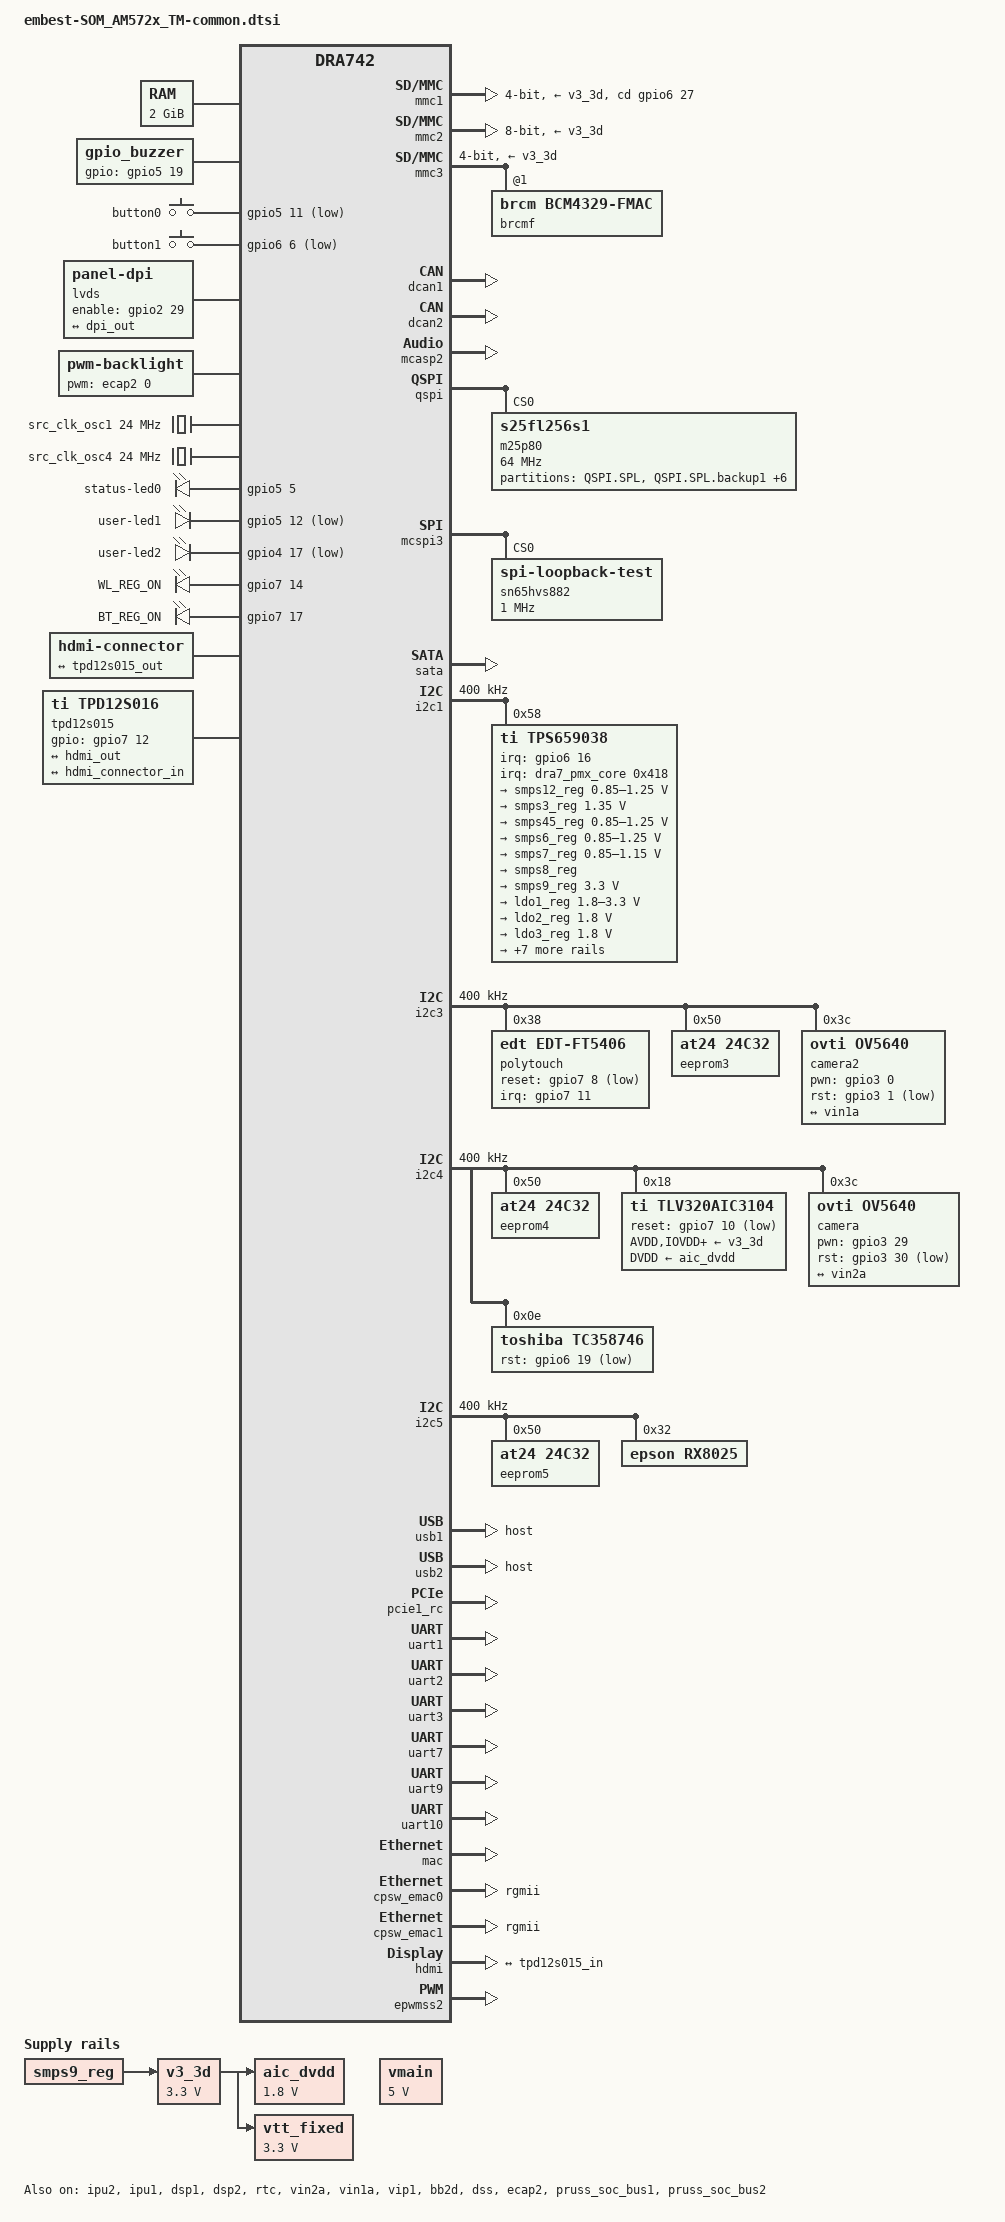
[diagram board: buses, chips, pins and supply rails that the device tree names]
/*
 * Copyright (C) 2017-2017 Embest - http://www.embest-tech.com/
 *
 * This program is free software; you can redistribute it and/or modify
 * it under the terms of the GNU General Public License version 2 as
 * published by the Free Software Foundation.
 */
/dts-v1/;

#include "dra74x.dtsi"
#include <dt-bindings/gpio/gpio.h>
#include <dt-bindings/interrupt-controller/irq.h>
#include "am57xx-industrial-grade.dtsi"

/ {
	compatible = "ti,am572x-beagle-x15", "ti,am5728", "ti,dra742", "ti,dra74", "ti,dra7";

	chosen {
		stdout-path = &uart3;
	};

	memory@0 {
		device_type = "memory";
		reg = <0x0 0x80000000 0x0 0x80000000>;		/*** Is size 2G? */
	};

       reserved-memory {
                #address-cells = <2>;
                #size-cells = <2>;
                ranges;

                ipu2_cma_pool: ipu2_cma@95800000 {
                        compatible = "shared-dma-pool";
                        reg = <0x0 0x95800000 0x0 0x3800000>;
                        reusable;
                        status = "okay";
                };

                dsp1_cma_pool: dsp1_cma@99000000 {
                        compatible = "shared-dma-pool";
                        reg = <0x0 0x99000000 0x0 0x4000000>;
                        reusable;
                        status = "okay";
                };

                ipu1_cma_pool: ipu1_cma@9d000000 {
                        compatible = "shared-dma-pool";
                        reg = <0x0 0x9d000000 0x0 0x2000000>;
                        reusable;
                        status = "okay";
                };

                dsp2_cma_pool: dsp2_cma@9f000000 {
                        compatible = "shared-dma-pool";
                        reg = <0x0 0x9f000000 0x0 0x800000>;
                        reusable;
                        status = "okay";
                };

                cmem_block_mem_0: cmem_block_mem@a0000000 {
                        reg = <0x0 0xa0000000 0x0 0x0c000000>;
                        no-map;
                        status = "okay";
                };
               
               cmem_block_mem_1_ocmc3: cmem_block_mem@40500000 {
                        reg = <0x0 0x40500000 0x0 0x100000>;
                        no-map;
                        status = "okay";
                };
        };


	aliases:aliases {
		display0 = &hdmi0;
		display1 = &lcd0;
		sound0 = &sound0;
		sound1 = &hdmi;
	};

	buzzer {
		pinctrl-names = "default";
		pinctrl-0 = <&buzzer_pin>;
		compatible = "gpio_buzzer";
		gpios = <&gpio5 19 GPIO_ACTIVE_HIGH>;
	};

	gpio_buttons: gpio_buttons@0 {
		compatible = "gpio-keys";
		pinctrl-names = "default";
	        pinctrl-0 = <&gpio_keys>;
		#address-cells = <1>;
		#size-cells = <0>;

		switch@1 {
			label = "button0";
			linux,code = <0x100>;
			gpios = <&gpio5 11 GPIO_ACTIVE_LOW>;
		};

		switch@2 {
			label = "button1";
			linux,code = <0x101>;
			gpios = <&gpio6 6 GPIO_ACTIVE_LOW>;
		};
	};

	sound0: sound0 {
                compatible = "simple-audio-card";
                simple-audio-card,name = "AM5728-Embest-TLV";
                simple-audio-card,widgets =
                        "Line", "Line Out",
			"Line", "Line In";
                simple-audio-card,routing =
			"Line Out",	"LLOUT",
			"Line Out",	"RLOUT",
			"MIC2L",	"Line In",
			"MIC2R",	"Line In";
                simple-audio-card,format = "dsp_b";
                simple-audio-card,bitclock-master = <&sound0_master>;
                simple-audio-card,frame-master = <&sound0_master>;
                simple-audio-card,bitclock-inversion;

                simple-audio-card,cpu {
                        sound-dai = <&mcasp2>;
                };

		sound0_master: simple-audio-card,codec {
                        sound-dai = <&tlv320aic3104>;
//			clocks = <&mcasp2_ahclk_mux>;
			clocks = <&clkout2_clk>;
                };
        };

	lcd0: display {
		compatible = "panel-dpi";
		label = "lvds";
 
		/*If there is a enable pin in LCD sch. you need to add this!*/
		pinctrl-names = "default";
		pinctrl-0 = <&lcd_enable_pin>;
		enable-gpios = <&gpio2 29 GPIO_ACTIVE_HIGH>;

		panel-timing {
			clock-frequency = <47500000>;
			hactive = <1024>;
			vactive = <600>;
			hfront-porch = <64>;
			hback-porch = <16>;
			hsync-len = <48>;
			vback-porch = <64>;
			vfront-porch = <16>;
			vsync-len = <3>;
			hsync-active = <1>;
			vsync-active = <1>;
			de-active = <1>;
			pixelclk-active = <1>;
		};

		port {
			lcd_in: endpoint {
				remote-endpoint = <&dpi_out>;
			};
		};
	};

	backlight {
		compatible = "pwm-backlight";
		pwms = <&ecap2 0 50000 0>;

		brightness-levels = <0 10 50 100 150 200 220 240 255>;

		default-brightness-level = <4>;
	};

	vmain: fixedregulator-vmain {
		compatible = "regulator-fixed";
		regulator-name = "VMAIN";
		regulator-min-microvolt = <5000000>;
		regulator-max-microvolt = <5000000>;
		regulator-always-on;
		regulator-boot-on;
	};

	v3_3d: fixedregulator-v3_3d {
		compatible = "regulator-fixed";
		regulator-name = "V3_3D";
		vin-supply = <&smps9_reg>;
		regulator-min-microvolt = <3300000>;
		regulator-max-microvolt = <3300000>;
		regulator-always-on;
		regulator-boot-on;
	};

	aic_dvdd: fixedregulator-aic_dvdd {
		compatible = "regulator-fixed";
		regulator-name = "aic_dvdd_fixed";
		vin-supply = <&v3_3d>;
		regulator-min-microvolt = <1800000>;
		regulator-max-microvolt = <1800000>;
		regulator-always-on;
                regulator-boot-on;

	};

	vtt_fixed: fixedregulator-vtt {
		/* TPS51200 */
		compatible = "regulator-fixed";
		regulator-name = "vtt_fixed";
		vin-supply = <&v3_3d>;
		regulator-min-microvolt = <3300000>;
		regulator-max-microvolt = <3300000>;
		regulator-always-on;
		regulator-boot-on;
	};

	src_clk_x1: src_clk_x1 {
		#clock-cells = <0>;
		compatible = "fixed-clock";
		clock-frequency = <20000000>;
	};
    src_clk_osc1: src_clk_osc1 {
        #clock-cells = <0>;
        compatible = "fixed-clock";
        clock-frequency = <24000000>;
    };
    src_clk_osc4: src_clk_osc4 {
        #clock-cells = <0>;
        compatible = "fixed-clock";
        clock-frequency = <24000000>;
    };
	
	leds {
		pinctrl-names = "default";
		pinctrl-0 = <&leds_pins_default>;
		compatible = "gpio-leds";
		led@0 {
			label = "status-led0";
			gpios = <&gpio5 5 GPIO_ACTIVE_HIGH>;
			linux,default-trigger = "heartbeat";
			default-state = "off";
		};

		led@1 {
			label = "user-led1";
			gpios = <&gpio5 12 GPIO_ACTIVE_LOW>;
			default-state = "off";
		};

		led@2 {
			label = "user-led2";
			gpios = <&gpio4 17 GPIO_ACTIVE_LOW>;
			default-state = "off";
		};

		led@3 {
			label = "WL_REG_ON";
			gpios = <&gpio7 14 GPIO_ACTIVE_HIGH>;
			default-state = "on";
		};		

		led@4 {
			label = "BT_REG_ON";
			gpios = <&gpio7 17 GPIO_ACTIVE_HIGH>;
			default-state = "on";
		};
	};

	hdmi0: connector@0 {
		compatible = "hdmi-connector";
		label = "hdmi";

		type = "a";

		port {
			hdmi_connector_in: endpoint {
				remote-endpoint = <&tpd12s015_out>;
			};
		};
	};

	tpd12s015: encoder@0 {
		compatible = "ti,tpd12s016", "ti,tpd12s015";

		gpios = <0>, /* optional CT_CP_HPD */
			<0>, /* optional LS_OE */
			<&gpio7 12 GPIO_ACTIVE_HIGH>;	/* HPD */

		ports {
			#address-cells = <1>;
			#size-cells = <0>;

			port@0 {
				reg = <0>;

				tpd12s015_in: endpoint@0 {
					remote-endpoint = <&hdmi_out>;
				};
			};

			port@1 {
				reg = <1>;

				tpd12s015_out: endpoint@0 {
					remote-endpoint = <&hdmi_connector_in>;
				};
			};
		};
	};


};

&cpu0 {
	vdd-supply = <&smps12_reg>;
};

&mmc1 {
	status = "okay";
	vmmc-supply = <&v3_3d>;
	vmmc_aux-supply = <&ldo1_reg>;
	bus-width = <4>;
	cd-gpios = <&gpio6 27 0>; /* gpio 219 */

	pinctrl-names = "default", "hs", "sdr12", "sdr25", "sdr50", "ddr50", "sdr104";
	pinctrl-0 = <&mmc1_pins_default>;
	pinctrl-1 = <&mmc1_pins_hs>;
	pinctrl-2 = <&mmc1_pins_sdr12>;
	pinctrl-3 = <&mmc1_pins_sdr25>;
	pinctrl-4 = <&mmc1_pins_sdr50>;
	pinctrl-5 = <&mmc1_pins_ddr50 &mmc1_iodelay_ddr50_conf>;
	pinctrl-6 = <&mmc1_pins_sdr104 &mmc1_iodelay_sdr104_conf>;
	max-frequency = <24000000>;
};

&mmc2 {
	status = "okay";
	vmmc-supply = <&v3_3d>;
	bus-width = <8>;
	ti,non-removable;
	max-frequency = <96000000>;
	no-1-8-v;
	/delete-property/ mmc-hs200-1_8v;

	pinctrl-names = "default", "hs", "ddr_1_8v";
	pinctrl-0 = <&mmc2_pins_default>;
	pinctrl-1 = <&mmc2_pins_hs>;
	pinctrl-2 = <&mmc2_pins_ddr_1_8v &mmc2_iodelay_ddr_1_8v_conf>;
};

&mmc3 {
	status = "okay";
	bus-width = <4>;
	vmmc-supply = <&v3_3d>;
	cap-power-off-card;
	keep-power-in-suspend;
	ti,non-removable;	
	//vmmc_aux-supply = <&ldo1_reg>;
	max-frequency = <2000000>;
	pinctrl-names = "default", "hs", "sdr12", "sdr25", "sdr50";
	pinctrl-0 = <&mmc3_pins_default>;
	pinctrl-1 = <&mmc3_pins_hs>;
	pinctrl-2 = <&mmc3_pins_sdr12>;
	pinctrl-3 = <&mmc3_pins_sdr25>;
	pinctrl-4 = <&mmc3_pins_sdr50>;
	#address-cells = <1>;
	#size-cells = <0>;
	brcmf: brcmf@0 {
		status = "okay";
		reg = <1>;
		//pinctrl-names = "default";
		//pinctrl-0 = <&brcm_wifi_reset>;
		//enable-gpios = <&gpio7 14 GPIO_ACTIVE_HIGH>;
		compatible = "brcm,bcm4329-fmac";
		sd_sgentry_align = <512>;
	};	
};

&dcan1 {
	status = "okay";
	pinctrl-names = "default", "sleep", "active";
	pinctrl-0 = <&dcan1_pins_sleep>;
	pinctrl-1 = <&dcan1_pins_sleep>;
	pinctrl-2 = <&dcan1_pins_default>;
};

&dcan2 {
	status = "okay";
	pinctrl-names = "default", "sleep", "active";
	pinctrl-0 = <&dcan2_pins_sleep>;
	pinctrl-1 = <&dcan2_pins_sleep>;
	pinctrl-2 = <&dcan2_pins_default>;
};

&ipu2 {
        status = "okay";
        memory-region = <&ipu2_cma_pool>;
        mboxes = <&mailbox6 &mbox_ipu2_ipc3x>;
        timers = <&timer3>;
        watchdog-timers = <&timer4>,<&timer9>;
};

&ipu1 {
        status = "okay";
        memory-region = <&ipu1_cma_pool>;
        mboxes = <&mailbox5 &mbox_ipu1_ipc3x>;
        timers = <&timer11>;
        watchdog-timers = <&timer7>,<&timer8>;
};

&dsp1 {
        status = "okay";
        memory-region = <&dsp1_cma_pool>;
        mboxes = <&mailbox5 &mbox_dsp1_ipc3x>;
        timers = <&timer5>;
        watchdog-timers = <&timer10>;
};

&dsp2 {
        status = "okay";
        memory-region = <&dsp2_cma_pool>;
        mboxes = <&mailbox6 &mbox_dsp2_ipc3x>;
        timers = <&timer6>;
        watchdog-timers = <&timer13>;
};

&mailbox5 {
        status = "okay";
        mbox_ipu1_ipc3x: mbox_ipu1_ipc3x {
                status = "okay";
        };
        mbox_dsp1_ipc3x: mbox_dsp1_ipc3x {
                status = "okay";
        };
};

&mailbox6 {
        status = "okay";
        mbox_ipu2_ipc3x: mbox_ipu2_ipc3x {
                status = "okay";
        };
        mbox_dsp2_ipc3x: mbox_dsp2_ipc3x {
                status = "okay";
        };
};

&mmu0_dsp1 {
        status = "okay";
};

&mmu1_dsp1 {
        status = "okay";
};

&mmu0_dsp2 {
        status = "okay";
};

&mmu1_dsp2 {
        status = "okay";
};

&mmu_ipu1 {
        status = "okay";
};

&mmu_ipu2 {
        status = "okay";
};



&mcasp2 {
        #sound-dai-cells = <0>;
        pinctrl-names = "default","sleep";
        pinctrl-0 = <&mcasp2_pins_default>;
	pinctrl-1 = <&mcasp2_pins_sleep>;
        status = "okay";

	assigned-clocks = <&mcasp2_ahclkx_mux>;
	assigned-clock-parents = <&sys_clkin2>;

        op-mode = <0>;  /* MCASP_IIS_MODE */
        tdm-slots = <2>;
        /* 4 serializers */
        serial-dir = <  /* 0: INACTIVE, 1: TX, 2: RX */
                1 2 0 0
        >;
        tx-num-evt = <32>;
        rx-num-evt = <32>;
};

&qspi {
	status = "okay";

	pinctrl-names = "default";
	pinctrl-0 = <&qspi1_pins_default>;

	spi-max-frequency = <64000000>;
	m25p80@0 {
		compatible = "s25fl256s1";
		spi-max-frequency = <64000000>;
		reg = <0>;
		spi-tx-bus-width = <1>;
		spi-rx-bus-width = <4>;
		#address-cells = <1>;
		#size-cells = <1>;

		/*
		 * MTD partition table.
		 */
		partition@0 {
			label = "QSPI.SPL";
			reg = <0x00000000 0x000030000>;
		};
		partition@1 {
			label = "QSPI.SPL.backup1";
			reg = <0x00030000 0x00010000>;
		};
		partition@2 {
			label = "QSPI.u-boot";
			reg = <0x00040000 0x00100000>;
		};
		partition@3 {
			label = "QSPI.u-boot-spl-os";
			reg = <0x00140000 0x00080000>;
		};
		partition@4 {
			label = "QSPI.u-boot-env";
			reg = <0x001C0000 0x00010000>;
		};
		partition@5 {
			label = "QSPI.u-boot-env.backup1";
			reg = <0x001D0000 0x00010000>;
		};
		partition@6 {
			label = "QSPI.kernel";
			reg = <0x001E0000 0x0800000>;
		};
		partition@7 {
			label = "QSPI.user-data";
			reg = <0x009E0000 0x1620000>;
		};
	};
};

&rtc {
	status = "okay";
	ext-clk-src;
};

&mcspi3 {
	status = "okay";
        pinctrl-names = "default";
        pinctrl-0 = <&spi3_pins_default>;
	ti,pindir-d0-out-d1-in;

	sn65hvs882: sn65hvs882@0 {
		compatible = "linux,spi-loopback-test";
		gpio-controller;
		#gpio-cells = <2>;

		reg = <0>;
		spi-max-frequency = <1000000>;
		spi-cpol;
	};
};

&sata {
	status = "okay";
};

&i2c1 {
	status = "okay";
	clock-frequency = <400000>;

	tps659038: tps659038@58 {
		compatible = "ti,tps659038";
		reg = <0x58>;
		interrupts-extended = <&gpio6 16 IRQ_TYPE_LEVEL_HIGH
			       &dra7_pmx_core 0x418>;
		#interrupt-cells = <2>;
		interrupt-controller;
		ti,system-power-controller;
		ti,palmas-override-powerhold;

		tps659038_pmic {
			compatible = "ti,tps659038-pmic";

			smps12-in-supply = <&vmain>;
			smps3-in-supply = <&vmain>;
			smps45-in-supply = <&vmain>;
			smps6-in-supply = <&vmain>;
			smps7-in-supply = <&vmain>;
			mps3-in-supply = <&vmain>;
			smps8-in-supply = <&vmain>;
			smps9-in-supply = <&vmain>;
			ldo1-in-supply = <&vmain>;
			ldo2-in-supply = <&vmain>;
			ldo3-in-supply = <&vmain>;
			ldo4-in-supply = <&vmain>;
			ldo9-in-supply = <&vmain>;
			ldoln-in-supply = <&vmain>;
			ldousb-in-supply = <&vmain>;
			ldortc-in-supply = <&vmain>;

			regulators {
				smps12_reg: smps12 {
					/* VDD_MPU */
					regulator-name = "smps12";
					regulator-min-microvolt = <850000>;
					regulator-max-microvolt = <1250000>;
					regulator-always-on;
					regulator-boot-on;
				};

				smps3_reg: smps3 {
					/* VDD_DDR EMIF1 EMIF2 */
					regulator-name = "smps3";
					regulator-min-microvolt = <1350000>;
					regulator-max-microvolt = <1350000>;
					regulator-always-on;
					regulator-boot-on;
				};

				smps45_reg: smps45 {
					/* VDD_DSPEVE on AM572 */
					/* VDD_IVA + VDD_DSP on AM571 */
					regulator-name = "smps45";
					regulator-min-microvolt = <850000>;
					regulator-max-microvolt = <1250000>;
					regulator-always-on;
					regulator-boot-on;
				};

				smps6_reg: smps6 {
					/* VDD_GPU */
					regulator-name = "smps6";
					regulator-min-microvolt = <850000>;
					regulator-max-microvolt = <1250000>;
					regulator-always-on;
					regulator-boot-on;
				};

				smps7_reg: smps7 {
					/* VDD_CORE */
					regulator-name = "smps7";
					regulator-min-microvolt = <850000>;	/*** 1.15V */
					regulator-max-microvolt = <1150000>;
					regulator-always-on;
					regulator-boot-on;
				};

				smps8_reg: smps8 {
					/* 5728 - VDD_IVAHD */			/*** 1.06V */
					/* 5718 - N.C. test point */
					regulator-name = "smps8";
				};

				smps9_reg: smps9 {
					/* VDD_3_3D */
					regulator-name = "smps9";
					regulator-min-microvolt = <3300000>;
					regulator-max-microvolt = <3300000>;
					regulator-always-on;
					regulator-boot-on;
				};

				ldo1_reg: ldo1 {
					/* VDDSHV8 - VSDMMC  */
					/* NOTE: on rev 1.3a, data supply */
					regulator-name = "ldo1";
					regulator-min-microvolt = <1800000>;
					regulator-max-microvolt = <3300000>;
					regulator-boot-on;
					regulator-always-on;
				};

				ldo2_reg: ldo2 {
					/* VDDSH18V */
					regulator-name = "ldo2";
					regulator-min-microvolt = <1800000>;
					regulator-max-microvolt = <1800000>;
					regulator-always-on;
					regulator-boot-on;
				};

				ldo3_reg: ldo3 {
					/* R1.3a 572x V1_8PHY_LDO3: USB, SATA */
					regulator-name = "ldo3";
					regulator-min-microvolt = <1800000>;
					regulator-max-microvolt = <1800000>;
					regulator-always-on;
					regulator-boot-on;
				};

				ldo4_reg: ldo4 {
					/* R1.3a 572x V1_8PHY_LDO4: PCIE, HDMI*/
					regulator-name = "ldo4";
					regulator-min-microvolt = <1800000>;
					regulator-max-microvolt = <1800000>;
					regulator-always-on;
					regulator-boot-on;
				};

				/* LDO5-8 unused */

				ldo9_reg: ldo9 {
					/* VDD_RTC  */
					regulator-name = "ldo9";
					regulator-min-microvolt = <840000>;
					regulator-max-microvolt = <1160000>;
					regulator-always-on;
					regulator-boot-on;
				};

				ldoln_reg: ldoln {
					/* VDDA_1V8_PLL */
					regulator-name = "ldoln";
					regulator-min-microvolt = <1800000>;
					regulator-max-microvolt = <1800000>;
					regulator-always-on;
					regulator-boot-on;
				};

				ldousb_reg: ldousb {
					/* VDDA_3V_USB: VDDA_USBHS33 */
					regulator-name = "ldousb";
					regulator-min-microvolt = <3300000>;
					regulator-max-microvolt = <3300000>;
					regulator-always-on;
					regulator-boot-on;
				};

				ldortc_reg: ldortc {
					/* VDDA_RTC  */
					regulator-name = "ldortc";
					regulator-min-microvolt = <1800000>;
					regulator-max-microvolt = <1800000>;
					regulator-always-on;
					regulator-boot-on;
				};

				regen1: regen1 {
					/* VDD_3V3_ON */
					regulator-name = "regen1";
					regulator-boot-on;
					regulator-always-on;
				};

				regen2: regen2 {
					/* Needed for PMIC internal resource */
					regulator-name = "regen2";
					regulator-boot-on;
					regulator-always-on;
				};
			};
		};
/*** need to modify in i2c1 */
		tps659038_rtc: tps659038_rtc {
			compatible = "ti,palmas-rtc";
			interrupt-parent = <&tps659038>;
			interrupts = <8 IRQ_TYPE_EDGE_FALLING>;
			wakeup-source;
		};

		tps659038_pwr_button: tps659038_pwr_button {
			compatible = "ti,palmas-pwrbutton";
			interrupt-parent = <&tps659038>;
			interrupts = <1 IRQ_TYPE_EDGE_FALLING>;
			wakeup-source;
			ti,palmas-long-press-seconds = <12>;
		};

		tps659038_gpio: tps659038_gpio {
			compatible = "ti,palmas-gpio";
			gpio-controller;
			#gpio-cells = <2>;
		};

		extcon_usb2: tps659038_usb {
			compatible = "ti,palmas-usb-vid";
			ti,enable-vbus-detection;
			ti,enable-id-detection;
			/* ID & VBUS GPIOs provided in board dts */
		};
	};

	tc358778: tc358778@0e {
		compatible = "toshiba,tc358778", "toshiba,tc358768";
		reg = <0x0e>;
		status = "disabled";

		clocks = <&src_clk_x1>;
		clock-names = "refclk";

		ports {
			#address-cells = <1>;
			#size-cells = <0>;

			port@0 {
				reg = <0>;
				tc358778_in: endpoint {
				/*	remote-endpoint = <&dpi_out>;
					data-lines = <24>; */
				};
			};

			port@1 {
				reg = <1>;
				tc358778_out: endpoint {
					/*
					 * lanes and remote-endpoint defined per
					 * panel.
					 */
				};
			};
		};
	};
};

&i2c3 {
	/*** designed for I2C touch Interface*/
	status = "okay";
	clock-frequency = <400000>;
	pinctrl-names = "default";
	pinctrl-0 = <&i2c3_pins>;

	polytouch: edt-ft5x06@38 {
		compatible = "edt,edt-ft5406", "edt,edt-ft5x06";
		reg = <0x38>;
		pinctrl-names = "default";
		pinctrl-0 = <&edt_ft5x06_pins>;
		interrupt-parent = <&gpio7>;
		interrupts = <11 IRQ_TYPE_EDGE_FALLING>;
		reset-gpios = <&gpio7 8 GPIO_ACTIVE_LOW>;
	};

	eeprom3: eeprom@50 {
		compatible = "at24,24c32";
		reg = <0x50>;
	};
camera2: ov5640@3c {
            compatible = "ovti,ov5640";
            reg = <0x3c>;
            clocks = <&src_clk_osc1>;
            clock-names = "xvclk";
           /* VIN1A_DE0 */
            pwn-gpios = <&gpio3 0 GPIO_ACTIVE_HIGH>;
            /* VIN1A_FLD0 */
            rst-gpios = <&gpio3 1 GPIO_ACTIVE_LOW>;
            /* xclk */
            pinctrl-names = "default";
            pinctrl-0 = <&vin1a_pins>;
            port {
              ov5640_2: endpoint {
              hsync-active = <GPIO_ACTIVE_LOW>;
              vsync-active = <GPIO_ACTIVE_LOW>;
              pclk-sample = <1>;
              link-frequencies = /bits/ 64 <70000000>;
              };
            };
        };
};

&i2c4 {
	status = "okay";
	clock-frequency = <400000>;
	pinctrl-names = "default";
	pinctrl-0 = <&i2c4_pins>;

	eeprom4: eeprom@50 {
		compatible = "at24,24c32";
		reg = <0x50>;
	};

	/* Audio */
	tlv320aic3104: tlv320aic3104@18 {
                #sound-dai-cells = <0>;
                compatible = "ti,tlv320aic3104";
                reg = <0x18>;
                pinctrl-names = "default";
                pinctrl-0 = <&tlv_rst_pin_default>;
                gpio-reset = <&gpio7 10 GPIO_ACTIVE_LOW>;
                status = "okay";
                adc-settle-ms = <40>;
		ai3x-micbias-vg = <0x02>;
                assigned-clocks = <&clkoutmux2_clk_mux>;
                assigned-clock-parents = <&sys_clk2_dclk_div>;

                AVDD-supply = <&v3_3d>;
                IOVDD-supply = <&v3_3d>;
                DRVDD-supply = <&v3_3d>;
                DVDD-supply = <&aic_dvdd>;
        };

	/* Parallel Camera */
camera: ov5640@3c {
            compatible = "ovti,ov5640";
            reg = <0x3c>;
            clocks = <&src_clk_osc1>;
            clock-names = "xvclk";
            /* am43xx
		clocks = <&clkout3_ck>;
		clock-names = "mclk";
		assigned-clocks = <&clkout3_mux_ck>, <&clkout3_post_div_ck>;
		assigned-clock-parents = <&sysclk_div>;
		assigned-clock-rates = <0>, <12500000>;		
            */
            /* TODO */
            /*
               clock-names = "csi_mclk";
               csi_id = <0>;
               mclk = <24000000>;
             */
            /* VIN2A_CLK0 */
            /*xclk-gpios = <&gpio3 28 GPIO_ACTIVE_HIGH>;*/
            /* VIN2A_DE0 */
            pwn-gpios = <&gpio3 29 GPIO_ACTIVE_HIGH>;
            /* VIN2A_FLD0 */
            rst-gpios = <&gpio3 30 GPIO_ACTIVE_LOW>;
            /* xclk */
            pinctrl-names = "default";
            pinctrl-0 = <&vin2a_pins>;
            /*
               clocks = <&clkout2_clk>;
             */
            port {
              ov5640_1: endpoint {
              hsync-active = <GPIO_ACTIVE_LOW>;
              vsync-active = <GPIO_ACTIVE_LOW>;
              pclk-sample = <1>;
              link-frequencies = /bits/ 64 <70000000>;
              };
            };
        };

	tc358746: tc358746@0e {
		compatible = "toshiba,tc358746";
		reg = <0x0e>;
		status = "okay";

		#clocks = <&src_clk_x1>;
		#clock-names = "refclk";

        rst-gpios = <&gpio6 19 GPIO_ACTIVE_LOW>;

		ports {
			#address-cells = <1>;
			#size-cells = <0>;

			port@0 {
				reg = <0>;
				tc358776_in: endpoint {
				/*	remote-endpoint = <&dpi_out>;
					data-lines = <24>; */
				};
			};

			port@1 {
				reg = <1>;
				tc358776_out: endpoint {
					/*
					 * lanes and remote-endpoint defined per
					 * panel.
					 */
				};
			};
		};
	};
 

};
&ov5640_1 {
 remote-endpoint = <&vin2a>;
};
&vin2a {
 status = "okay";
 endpoint@2 {
  slave-mode;
  remote-endpoint = <&ov5640_1>;
  bus-width = <8>;
  hsync-active = <GPIO_ACTIVE_LOW>;
  vsync-active = <GPIO_ACTIVE_LOW>;
 };
};
&ov5640_2 {
 remote-endpoint = <&vin1a>;
};
&vin1a {
 status = "okay";
 endpoint@1 {
  slave-mode;
  remote-endpoint = <&ov5640_2>;
  bus-width = <8>;
  hsync-active = <GPIO_ACTIVE_LOW>;
  vsync-active = <GPIO_ACTIVE_LOW>;
 };
};
&vip1 {
 status = "okay";
};
&i2c5 {
	status = "okay";
	clock-frequency = <400000>;
	pinctrl-names = "default";
	pinctrl-0 = <&i2c5_pins>;

	eeprom5: eeprom@50 {
		compatible = "at24,24c32";
		reg = <0x50>;
	};

	rx8025: rx8025@32 {
		compatible = "epson,rx8025";
		reg = <0x32>;
		status = "okay";
	};
};

&usb2_phy1 {
	phy-supply = <&ldousb_reg>;
};

&usb2_phy2 {
	phy-supply = <&ldousb_reg>;
};

&usb1 {
	dr_mode = "host";
};

&usb2 {
	/*
	 * Stand alone usage is peripheral only.
	 * However, with some resistor modifications
	 * this port can be used via expansion connectors
	 * as "host" or "dual-role". If so, provide
	 * the necessary dr_mode override in the expansion
	 * board's DT.
	 */
	dr_mode = "host";
};

&pcie1_rc {
 status = "okay";
};

&uart1 {
	status = "okay";
	pinctrl-names = "default";
	pinctrl-0 = <&uart1_pins>;
};

&uart2 {
	/*** designed for RS485 */
	status = "okay";
	pinctrl-names = "default";
	pinctrl-0 = <&uart2_pins>;
	rts-gpio = <&gpio7 31 GPIO_ACTIVE_HIGH>;
	rs485-rts-active-high;
	rs485-rx-during-tx;
	rs485-rts-delay = <1 1>;
	linux,rs485-enabled-at-boot-time;
};

&uart3 {
	/*** debug serial port */
	status = "okay";
	interrupts-extended = <&crossbar_mpu GIC_SPI 69 IRQ_TYPE_LEVEL_HIGH
			       &dra7_pmx_core 0x248>;
};

&uart7 {/* for WIFI-BT */
	pinctrl-names = "default";
	pinctrl-0 = <&uart7_pins>;
	status = "okay";
};

&uart9 {
	pinctrl-names = "default";
	pinctrl-0 = <&uart9_pins>;
	status = "okay";
	rts-gpio = <&gpio5 10 GPIO_ACTIVE_HIGH>;
	rs485-rts-active-high;
	rs485-rx-during-tx;
	rs485-rts-delay = <1 1>;
	linux,rs485-enabled-at-boot-time;
};

&uart10 {
	status = "okay";
	pinctrl-names = "default";
	pinctrl-0 = <&uart10_pins>;

};

&mac {
	status = "okay";
	dual_emac;
};

&cpsw_emac0 {
	phy_id = <&davinci_mdio>, <4>;
	phy-mode = "rgmii";
	dual_emac_res_vlan = <1>;
};

&cpsw_emac1 {
	phy_id = <&davinci_mdio>, <6>;
	phy-mode = "rgmii";
	dual_emac_res_vlan = <2>;
};

&bb2d {
	status = "okay";
};

&hdmi {
	status = "okay";
	/*
	 * XXX: Support AM572x-Rev 1.2a. this is wrong for AM571x-rev 1.3a,
	 * AM572x-Rev1.3a - but thanks to always-on, they work.
	 * TODO: SWITCH TO LDO4 once rev 1.2a is deprecated
	 * (on rev 1.3a availability)
	 */
	vdda-supply = <&ldo3_reg>;

	port {
		hdmi_out: endpoint {
			remote-endpoint = <&tpd12s015_in>;
		};
	};
};


&dss {
	status = "okay";
	pinctrl-names = "default";
	pinctrl-0 = <&dss_dpi_pins>;

	vdda_video-supply = <&ldoln_reg>;

	ports {
		#address-cells = <1>;
		#size-cells = <0>;

		port@0 {
			reg = <0>;

			dpi_out: endpoint {
				remote-endpoint = <&lcd_in>;
				data-lines = <24>;
			};
		};
	};
};

&epwmss2 {
	status = "okay";
};

&ecap2 {
	status = "okay";
	pinctrl-names = "default";
	pinctrl-0 = <&ehrpwm2_pins>;
};

&mailbox3 {
	status = "okay";
	mbox_pru1_0: mbox_pru1_0 {
		status = "okay";
	};
	mbox_pru1_1: mbox_pru1_1 {
		status = "okay";
	};
};

&mailbox4 {
	status = "okay";
	mbox_pru2_0: mbox_pru2_0 {
		status = "okay";
	};
	mbox_pru2_1: mbox_pru2_1 {
		status = "okay";
	};
};

&pruss_soc_bus1 {
	status = "okay";

	pruss1: pruss@4b200000 {
		status = "okay";

		pru1_0: pru@4b234000 {
			interrupt-parent = <&pruss1_intc>;
			interrupts = <16>, <17>;
			interrupt-names = "vring", "kick";
			status = "okay";
		};

		pru1_1: pru@4b238000 {
			interrupt-parent = <&pruss1_intc>;
			interrupts = <18>, <19>;
			interrupt-names = "vring", "kick";
			status = "okay";
		};
	};
};

&pruss_soc_bus2 {
	status = "okay";

	pruss2: pruss@4b280000 {
		status = "okay";

		pru2_0: pru@4b2b4000 {
			interrupt-parent = <&pruss2_intc>;
			interrupts = <16>, <17>;
			interrupt-names = "vring", "kick";
			status = "okay";
		};

		pru2_1: pru@4b2b8000 {
			interrupt-parent = <&pruss2_intc>;
			interrupts = <18>, <19>;
			interrupt-names = "vring", "kick";
			status = "okay";
		};
	};
};

&dra7_pmx_core {
	gpio_keys: gpio_keys {
		pinctrl-single,pins = <
                        0x2d8 (PIN_INPUT_PULLUP | MUX_MODE14)  /* mcasp1_axr9.gpio5_11 */
			0x2f0 (PIN_INPUT_PULLUP | MUX_MODE14)  /* mcasp1_axr5.gpio6_6 */
                >;
	};

	buzzer_pin: buzzer_pin {
		pinctrl-single,pins = <
			0x24c (PIN_OUTPUT_PULLUP | MUX_MODE14)	/* uart3_txd.gpio5_19 */
		>;
	};

	edt_ft5x06_pins: edt_ft5x06_pins {
	       pinctrl-single,pins = <
        	   	0x3a8 (PIN_OUTPUT | MUX_MODE14) /* spi1_cs1.gpio7_8 */
           		0x3b4 (PIN_INPUT | MUX_MODE14) /* spi1_sclk.gpio7_11 */
       		>;
	};

	tlv_rst_pin_default: tlv_rst_pin_default {
		pinctrl-single,pins = <
			0x3b0 (PIN_OUTPUT_PULLUP | MUX_MODE14) /* spi1_cs0.gpio7_10 */
		>;
	};

	mcasp2_pins_default: mcasp2_pins_default {
		pinctrl-single,pins = <
			0x298 (PIN_OUTPUT_PULLDOWN | MUX_MODE3) /* xref_clk1.mcasp2_ahclkx */
			0x2f4 (PIN_INPUT_PULLDOWN | MUX_MODE0) /* mcasp2_aclkx.mcasp2_aclkx */
			0x304 (PIN_OUTPUT_PULLDOWN | MUX_MODE0) /* mcasp2_axr0.mcasp2_axr0 */
			0x308 (PIN_INPUT_PULLDOWN | MUX_MODE0) /* mcasp2_axr1.mcasp2_axr1 */
			0x2f8 (PIN_INPUT_PULLDOWN | MUX_MODE0) /* mcasp2_fsx.mcasp2_fsx */
		>;
	};

	mcasp2_pins_sleep: mcasp2_pins_sleep {
                pinctrl-single,pins = <
                        0x298 (PIN_INPUT | MUX_MODE15) /* xref_clk1.mcasp2_ahclkx */
                        0x2f4 (PIN_INPUT | MUX_MODE15) /* mcasp2_aclkx.mcasp2_aclkx */
                        0x304 (PIN_INPUT | MUX_MODE15) /* mcasp2_axr0.mcasp2_axr0 */
                        0x308 (PIN_INPUT | MUX_MODE15) /* mcasp2_axr1.mcasp2_axr1 */
                        0x2f8 (PIN_INPUT | MUX_MODE15) /* mcasp2_fsx.mcasp2_fsx */
                >;
        };

	lcd_enable_pin: lcd_enable_pin {
		pinctrl-single,pins = <
			DRA7XX_CORE_IOPAD(0x371c, PIN_OUTPUT | MUX_MODE14) /* B17:mcasp2_axr6, gpio2_29 */
			DRA7XX_CORE_IOPAD(0x35d0, PIN_OUTPUT_PULLUP | MUX_MODE14) /* B11:vout1_fld, gpio4_21*/
		>;
	};

	ehrpwm2_pins: ehrpwm2_pins {
		pinctrl-single,pins = <
			DRA7XX_CORE_IOPAD(0x37a0, (PIN_OUTPUT | MUX_MODE10)) /* mmc3_dat7.eCAP3_in_PWM3_out (AB5) */
		>;
	};

       dss_dpi_pins: dss_pins {
               pinctrl-single,pins = <
                       DRA7XX_CORE_IOPAD(0x35C8, PIN_OUTPUT_PULLUP | MUX_MODE0) /* vout1_clk */
                       DRA7XX_CORE_IOPAD(0x35CC, PIN_OUTPUT_PULLUP | MUX_MODE0) /* vout1_de */
//                       DRA7XX_CORE_IOPAD(0x35D0, PIN_OUTPUT_PULLUP | MUX_MODE0) /* vout1_fld */
                       DRA7XX_CORE_IOPAD(0x35D4, PIN_OUTPUT_PULLUP | MUX_MODE0) /* vout1_hsync */
                       DRA7XX_CORE_IOPAD(0x35D8, PIN_OUTPUT_PULLUP | MUX_MODE0) /* vout1_vsync */
                       DRA7XX_CORE_IOPAD(0x35DC, PIN_OUTPUT_PULLUP | MUX_MODE0) /* vout1_d0 */
                       DRA7XX_CORE_IOPAD(0x35E0, PIN_OUTPUT_PULLUP | MUX_MODE0) /* vout1_d1 */
                       DRA7XX_CORE_IOPAD(0x35E4, PIN_OUTPUT_PULLUP | MUX_MODE0) /* vout1_d2 */
                       DRA7XX_CORE_IOPAD(0x35E8, PIN_OUTPUT_PULLUP | MUX_MODE0) /* vout1_d3 */
                       DRA7XX_CORE_IOPAD(0x35EC, PIN_OUTPUT_PULLUP | MUX_MODE0) /* vout1_d4 */
                       DRA7XX_CORE_IOPAD(0x35F0, PIN_OUTPUT_PULLUP | MUX_MODE0) /* vout1_d5 */
                       DRA7XX_CORE_IOPAD(0x35F4, PIN_OUTPUT_PULLUP | MUX_MODE0) /* vout1_d6 */
                       DRA7XX_CORE_IOPAD(0x35F8, PIN_OUTPUT_PULLUP | MUX_MODE0) /* vout1_d7 */
                       DRA7XX_CORE_IOPAD(0x35FC, PIN_OUTPUT_PULLUP | MUX_MODE0) /* vout1_d8 */
                       DRA7XX_CORE_IOPAD(0x3600, PIN_OUTPUT_PULLUP | MUX_MODE0) /* vout1_d9 */
                       DRA7XX_CORE_IOPAD(0x3604, PIN_OUTPUT_PULLUP | MUX_MODE0) /* vout1_d10 */
                       DRA7XX_CORE_IOPAD(0x3608, PIN_OUTPUT_PULLUP | MUX_MODE0) /* vout1_d11 */
                       DRA7XX_CORE_IOPAD(0x360C, PIN_OUTPUT_PULLUP | MUX_MODE0) /* vout1_d12 */
                       DRA7XX_CORE_IOPAD(0x3610, PIN_OUTPUT_PULLUP | MUX_MODE0) /* vout1_d13 */
                       DRA7XX_CORE_IOPAD(0x3614, PIN_OUTPUT_PULLUP | MUX_MODE0) /* vout1_d14 */
                       DRA7XX_CORE_IOPAD(0x3618, PIN_OUTPUT_PULLUP | MUX_MODE0) /* vout1_d15 */
                       DRA7XX_CORE_IOPAD(0x361C, PIN_OUTPUT_PULLUP | MUX_MODE0) /* vout1_d16 */
                       DRA7XX_CORE_IOPAD(0x3620, PIN_OUTPUT_PULLUP | MUX_MODE0) /* vout1_d17 */
                       DRA7XX_CORE_IOPAD(0x3624, PIN_OUTPUT_PULLUP | MUX_MODE0) /* vout1_d18 */
                       DRA7XX_CORE_IOPAD(0x3628, PIN_OUTPUT_PULLUP | MUX_MODE0) /* vout1_d19 */
                       DRA7XX_CORE_IOPAD(0x362C, PIN_OUTPUT_PULLUP | MUX_MODE0) /* vout1_d20 */
                       DRA7XX_CORE_IOPAD(0x3630, PIN_OUTPUT_PULLUP | MUX_MODE0) /* vout1_d21 */
                       DRA7XX_CORE_IOPAD(0x3634, PIN_OUTPUT_PULLUP | MUX_MODE0) /* vout1_d22 */
                       DRA7XX_CORE_IOPAD(0x3638, PIN_OUTPUT_PULLUP | MUX_MODE0) /* vout1_d23 */
		>;
	};

	leds_pins_default: leds_pins_default {
		pinctrl-single,pins = <
			DRA7XX_CORE_IOPAD(0x36c0, (PIN_OUTPUT | MUX_MODE14)) /* mcasp1_axr3.gpio5_5 */
			DRA7XX_CORE_IOPAD(0x36dc, (PIN_OUTPUT | MUX_MODE14)) /* mcasp1_axr10.gpio5_12 */
			DRA7XX_CORE_IOPAD(0x36e0, (PIN_OUTPUT | MUX_MODE14)) /* mcasp1_axr11.gpio4_17 */
			DRA7XX_CORE_IOPAD(0x37c0, (PIN_OUTPUT | MUX_MODE14)) /*WL_REG_ON A26.spi2_sclk.gpio7_14  */						
			DRA7XX_CORE_IOPAD(0x37cc, (PIN_OUTPUT | MUX_MODE14)) /*BT_REG_ON B24.spi2_cs0.gpio7_17  */	
			/* DO  */
			DRA7XX_CORE_IOPAD(0x36bc, (PIN_OUTPUT | MUX_MODE14)) /* mcasp1_axr2.gpio5_4 */
			DRA7XX_CORE_IOPAD(0x36a8, (PIN_OUTPUT | MUX_MODE14)) /* mcasp1_fsx. gpio7_30 */
			/* DI  */
			DRA7XX_CORE_IOPAD(0x358c, (PIN_INPUT | MUX_MODE14)) /* vin2a_d9.gpio4_10 */
			DRA7XX_CORE_IOPAD(0x3590, (PIN_INPUT | MUX_MODE14)) /* vin2a_d10.gpio4_11 */
		>;
	};

	/* SPI3 pins */
	spi3_pins_default: spi3_pins_default {
		pinctrl-single,pins = <
			DRA7XX_CORE_IOPAD(0x3740, (PIN_OUTPUT_PULLUP | MUX_MODE2)) /* mcasp4_axr1.spi3_cs0 */
			DRA7XX_CORE_IOPAD(0x3734, (PIN_OUTPUT_PULLUP | MUX_MODE2)) /* mcasp4_aclkx.spi3_sclk */
			DRA7XX_CORE_IOPAD(0x373c, (PIN_OUTPUT_PULLUP | MUX_MODE2)) /* mcasp4_axr0.spi3_d0 */
			DRA7XX_CORE_IOPAD(0x3738, (PIN_INPUT_PULLUP | MUX_MODE2)) /* mcasp4_fsx.spi3_d1 */
		>;
	};

	/* I2C3 pins */
	i2c3_pins: i2c3_pins {
		pinctrl-single,pins = <
			DRA7XX_CORE_IOPAD(0x3778, (PIN_INPUT_PULLUP | MUX_MODE2)) /* gpio6_11.i2c3_scl */
			DRA7XX_CORE_IOPAD(0x3774, (PIN_INPUT_PULLUP | MUX_MODE2)) /* gpio6_10.i2c3_sda */
		>;
	};

	/* I2C4 pins */
	i2c4_pins: i2c4_pins {
		pinctrl-single,pins = <
			DRA7XX_CORE_IOPAD(0x36b0, (PIN_INPUT | MUX_MODE10)) /* mcasp1_fsr.i2c4_scl */
			DRA7XX_CORE_IOPAD(0x36ac, (PIN_INPUT | MUX_MODE10)) /* mcasp1_aclkr.i2c4_sda */
		>;
	};

	/* I2C5 pins */
	i2c5_pins: i2c5_pins {
		pinctrl-single,pins = <
			DRA7XX_CORE_IOPAD(0x3748, (PIN_INPUT | MUX_MODE4)) /* mcasp5_fsx.i2c5_scl */
			DRA7XX_CORE_IOPAD(0x3744, (PIN_INPUT | MUX_MODE4)) /* mcasp5_aclkx.i2c5_sda */
		>;
	};


	/* UART1 pins: rxd & txd */
	uart1_pins: uart1_pins {
		pinctrl-single,pins = <
			DRA7XX_CORE_IOPAD(0x37e0, (PIN_INPUT_PULLUP  | MUX_MODE0)) /* uart1_rxd.uart1_rxd */
			DRA7XX_CORE_IOPAD(0x37e4, (PIN_OUTPUT_PULLUP | MUX_MODE0)) /* uart1_txd.uart1_txd */
		>;
	};

	/* UART2 pins: rxd & txd */
	uart2_pins: uart2_pins {
		pinctrl-single,pins = <
			DRA7XX_CORE_IOPAD(0x37f0, (PIN_INPUT_PULLUP  | MUX_MODE4)) /* uart2_rxd.uart2_rxd */
			DRA7XX_CORE_IOPAD(0x37f4, (PIN_OUTPUT_PULLUP | MUX_MODE0)) /* uart2_txd.uart2_txd */
			DRA7XX_CORE_IOPAD(0x36a4, (PIN_OUTPUT_PULLDOWN | MUX_MODE14)) /* mcasp1_aclkx.gpio7_31 */
		>;
	};

	/* UART7 pins: rxd & txd */
	uart7_pins: uart7_pins {
		pinctrl-single,pins = <
			DRA7XX_CORE_IOPAD(0x3724, (PIN_INPUT  | MUX_MODE3)) /* mcasp3_aclkx.uart7_rxd */
			DRA7XX_CORE_IOPAD(0x3728, (PIN_OUTPUT | MUX_MODE3)) /* mcasp1_fsx.uart7_txd */
//			DRA7XX_CORE_IOPAD(0x372C, (PIN_OUTPUT | MUX_MODE3)) /* mcasp3_axr0.uart7_ctsn B19 */
//			DRA7XX_CORE_IOPAD(0x3730, (PIN_OUTPUT | MUX_MODE3)) /* mcasp3_axr1.uart7_rtsn C17 */
		>;
	};

	/* UART9 pins: rxd & txd */
	uart9_pins: uart9_pins {
		pinctrl-single,pins = <
			DRA7XX_CORE_IOPAD(0x37e8, (PIN_INPUT  | MUX_MODE2)) /* uart1_ctsn.uart9_rxd */
			DRA7XX_CORE_IOPAD(0x37ec, (PIN_OUTPUT | MUX_MODE2)) /* uart1_rtsn.uart9_txd */
			DRA7XX_CORE_IOPAD(0x36d4, (PIN_OUTPUT_PULLDOWN | MUX_MODE14)) /* mcasp1_axr8 .gpio5_10 */
		>;
	};

	/* UART10 pins: rxd & txd */
	uart10_pins: uart10_pins {
	       pinctrl-single,pins = <
		       DRA7XX_CORE_IOPAD(0x3794, (PIN_INPUT_PULLUP  | MUX_MODE2)) /* mmc3_data4.uart10_rxd */
		       DRA7XX_CORE_IOPAD(0x3798, (PIN_OUTPUT_PULLUP | MUX_MODE2)) /* mmc3_data5.uart10_txd */
	       >;
	};

	dcan1_pins_default: dcan1_pins_default {
		pinctrl-single,pins = <
			DRA7XX_CORE_IOPAD(0x37d0, PIN_OUTPUT_PULLUP | MUX_MODE0)	/* dcan1_tx */
			DRA7XX_CORE_IOPAD(0x37d4, PIN_INPUT_PULLUP | MUX_MODE0)		/* dcan1_rx */
		>;
	};

	dcan1_pins_sleep: dcan1_pins_sleep {
		pinctrl-single,pins = <
			DRA7XX_CORE_IOPAD(0x37d0, MUX_MODE15 | PULL_UP)	/* dcan1_tx.off */
			DRA7XX_CORE_IOPAD(0x37d4, MUX_MODE15 | PULL_UP)	/* dcan1_rx.off */
		>;
	};

	dcan2_pins_default: dcan2_pins_default {
		pinctrl-single,pins = <
			DRA7XX_CORE_IOPAD(0x3688, PIN_OUTPUT_PULLUP | MUX_MODE2)	/* gpio6_14,dcan2_tx */
			DRA7XX_CORE_IOPAD(0x368c, PIN_INPUT_PULLUP | MUX_MODE2)		/* gpio6_14,dcan2_rx */
		>;
	};

	dcan2_pins_sleep: dcan2_pins_sleep {
		pinctrl-single,pins = <
			DRA7XX_CORE_IOPAD(0x3688, MUX_MODE15 | PULL_UP)	/* dcan2_tx.off */
			DRA7XX_CORE_IOPAD(0x368c, MUX_MODE15 | PULL_UP)	/* dcan2_rx.off */
		>;
	};
	mmc1_pins_default: mmc1_pins_default {
		pinctrl-single,pins = <
			0x354 (PIN_INPUT_PULLUP | MUX_MODE0) /* mmc1_clk.clk */
			0x358 (PIN_INPUT_PULLUP | MUX_MODE0) /* mmc1_cmd.cmd */
			0x35c (PIN_INPUT_PULLUP | MUX_MODE0) /* mmc1_dat0.dat0 */
			0x360 (PIN_INPUT_PULLUP | MUX_MODE0) /* mmc1_dat1.dat1 */
			0x364 (PIN_INPUT_PULLUP | MUX_MODE0) /* mmc1_dat2.dat2 */
			0x368 (PIN_INPUT_PULLUP | MUX_MODE0) /* mmc1_dat3.dat3 */
		>;
	};

	mmc1_pins_sdr12: pinmux_mmc1_sdr12_pins {
		pinctrl-single,pins = <
			0x354 (PIN_INPUT_PULLUP | MUX_MODE0)	/* mmc1_clk.clk */
			0x358 (PIN_INPUT_PULLUP | MUX_MODE0)	/* mmc1_cmd.cmd */
			0x35c (PIN_INPUT_PULLUP | MUX_MODE0)	/* mmc1_dat0.dat0 */
			0x360 (PIN_INPUT_PULLUP | MUX_MODE0)	/* mmc1_dat1.dat1 */
			0x364 (PIN_INPUT_PULLUP | MUX_MODE0)	/* mmc1_dat2.dat2 */
			0x368 (PIN_INPUT_PULLUP | MUX_MODE0)	/* mmc1_dat3.dat3 */
		>;
	};

	mmc1_pins_hs: mmc1_pins_hs {
		pinctrl-single,pins = <
			0x354 (PIN_INPUT_PULLUP | MUX_VIRTUAL_MODE11 | MUX_MODE0) /* mmc1_clk.clk */
			0x358 (PIN_INPUT_PULLUP | MUX_VIRTUAL_MODE11 | MUX_MODE0) /* mmc1_cmd.cmd */
			0x35c (PIN_INPUT_PULLUP | MUX_VIRTUAL_MODE11 | MUX_MODE0) /* mmc1_dat0.dat0 */
			0x360 (PIN_INPUT_PULLUP | MUX_VIRTUAL_MODE11 | MUX_MODE0) /* mmc1_dat1.dat1 */
			0x364 (PIN_INPUT_PULLUP | MUX_VIRTUAL_MODE11 | MUX_MODE0) /* mmc1_dat2.dat2 */
			0x368 (PIN_INPUT_PULLUP | MUX_VIRTUAL_MODE11 | MUX_MODE0) /* mmc1_dat3.dat3 */
		>;
	};

	mmc1_pins_sdr25: pinmux_mmc1_sdr25_pins {
		pinctrl-single,pins = <
			0x354 (PIN_INPUT_PULLUP | MUX_VIRTUAL_MODE11 | MUX_MODE0)	/* mmc1_clk.clk */
			0x358 (PIN_INPUT_PULLUP | MUX_VIRTUAL_MODE11 | MUX_MODE0)	/* mmc1_cmd.cmd */
			0x35c (PIN_INPUT_PULLUP | MUX_VIRTUAL_MODE11 | MUX_MODE0)	/* mmc1_dat0.dat0 */
			0x360 (PIN_INPUT_PULLUP | MUX_VIRTUAL_MODE11 | MUX_MODE0)	/* mmc1_dat1.dat1 */
			0x364 (PIN_INPUT_PULLUP | MUX_VIRTUAL_MODE11 | MUX_MODE0)	/* mmc1_dat2.dat2 */
			0x368 (PIN_INPUT_PULLUP | MUX_VIRTUAL_MODE11 | MUX_MODE0)	/* mmc1_dat3.dat3 */
		>;
	};

	mmc1_pins_sdr50: pinmux_mmc1_sdr50_pins {
		pinctrl-single,pins = <
			0x354 (PIN_INPUT_PULLUP | MUX_VIRTUAL_MODE10 | MUX_MODE0)	/* mmc1_clk.clk */
			0x358 (PIN_INPUT_PULLUP | MUX_VIRTUAL_MODE10 | MUX_MODE0)	/* mmc1_cmd.cmd */
			0x35c (PIN_INPUT_PULLUP | MUX_VIRTUAL_MODE10 | MUX_MODE0)	/* mmc1_dat0.dat0 */
			0x360 (PIN_INPUT_PULLUP | MUX_VIRTUAL_MODE10 | MUX_MODE0)	/* mmc1_dat1.dat1 */
			0x364 (PIN_INPUT_PULLUP | MUX_VIRTUAL_MODE10 | MUX_MODE0)	/* mmc1_dat2.dat2 */
			0x368 (PIN_INPUT_PULLUP | MUX_VIRTUAL_MODE10 | MUX_MODE0)	/* mmc1_dat3.dat3 */
		>;
	};

	mmc1_pins_ddr50: pinmux_mmc1_ddr50_pins {
		pinctrl-single,pins = <
			0x354 (PIN_INPUT_PULLUP | MODE_SELECT | MUX_MODE0)	/* mmc1_clk.clk */
			0x358 (PIN_INPUT_PULLUP | MODE_SELECT | MUX_MODE0)	/* mmc1_cmd.cmd */
			0x35c (PIN_INPUT_PULLUP | MODE_SELECT | MUX_MODE0)	/* mmc1_dat0.dat0 */
			0x360 (PIN_INPUT_PULLUP | MODE_SELECT | MUX_MODE0)	/* mmc1_dat1.dat1 */
			0x364 (PIN_INPUT_PULLUP | MODE_SELECT | MUX_MODE0)	/* mmc1_dat2.dat2 */
			0x368 (PIN_INPUT_PULLUP | MODE_SELECT | MUX_MODE0)	/* mmc1_dat3.dat3 */
		>;
	};

	mmc1_pins_sdr104: pinmux_mmc1_sdr104_pins {
		pinctrl-single,pins = <
			0x354 (PIN_INPUT_PULLUP | MODE_SELECT | MUX_MODE0)	/* mmc1_clk.clk */
			0x358 (PIN_INPUT_PULLUP | MODE_SELECT | MUX_MODE0)	/* mmc1_cmd.cmd */
			0x35c (PIN_INPUT_PULLUP | MODE_SELECT | MUX_MODE0)	/* mmc1_dat0.dat0 */
			0x360 (PIN_INPUT_PULLUP | MODE_SELECT | MUX_MODE0)	/* mmc1_dat1.dat1 */
			0x364 (PIN_INPUT_PULLUP | MODE_SELECT | MUX_MODE0)	/* mmc1_dat2.dat2 */
			0x368 (PIN_INPUT_PULLUP | MODE_SELECT | MUX_MODE0)	/* mmc1_dat3.dat3 */
		>;
	};

	mmc2_pins_default: mmc2_pins_default {
		pinctrl-single,pins = <
			0x9c (PIN_INPUT_PULLUP | MUX_MODE1) /* gpmc_a23.mmc2_clk */
			0xb0 (PIN_INPUT_PULLUP | MUX_MODE1) /* gpmc_cs1.mmc2_cmd */
			0xa0 (PIN_INPUT_PULLUP | MUX_MODE1) /* gpmc_a24.mmc2_dat0 */
			0xa4 (PIN_INPUT_PULLUP | MUX_MODE1) /* gpmc_a25.mmc2_dat1 */
			0xa8 (PIN_INPUT_PULLUP | MUX_MODE1) /* gpmc_a26.mmc2_dat2 */
			0xac (PIN_INPUT_PULLUP | MUX_MODE1) /* gpmc_a27.mmc2_dat3 */
			0x8c (PIN_INPUT_PULLUP | MUX_MODE1) /* gpmc_a19.mmc2_dat4 */
			0x90 (PIN_INPUT_PULLUP | MUX_MODE1) /* gpmc_a20.mmc2_dat5 */
			0x94 (PIN_INPUT_PULLUP | MUX_MODE1) /* gpmc_a21.mmc2_dat6 */
			0x98 (PIN_INPUT_PULLUP | MUX_MODE1) /* gpmc_a22.mmc2_dat7 */
		>;
	};

	mmc2_pins_hs: mmc2_pins_hs {
		pinctrl-single,pins = <
			0x9c (PIN_INPUT_PULLUP | MUX_MODE1) /* gpmc_a23.mmc2_clk */
			0xb0 (PIN_INPUT_PULLUP | MUX_MODE1) /* gpmc_cs1.mmc2_cmd */
			0xa0 (PIN_INPUT_PULLUP | MUX_MODE1) /* gpmc_a24.mmc2_dat0 */
			0xa4 (PIN_INPUT_PULLUP | MUX_MODE1) /* gpmc_a25.mmc2_dat1 */
			0xa8 (PIN_INPUT_PULLUP | MUX_MODE1) /* gpmc_a26.mmc2_dat2 */
			0xac (PIN_INPUT_PULLUP | MUX_MODE1) /* gpmc_a27.mmc2_dat3 */
			0x8c (PIN_INPUT_PULLUP | MUX_MODE1) /* gpmc_a19.mmc2_dat4 */
			0x90 (PIN_INPUT_PULLUP | MUX_MODE1) /* gpmc_a20.mmc2_dat5 */
			0x94 (PIN_INPUT_PULLUP | MUX_MODE1) /* gpmc_a21.mmc2_dat6 */
			0x98 (PIN_INPUT_PULLUP | MUX_MODE1) /* gpmc_a22.mmc2_dat7 */
		>;
	};

	mmc2_pins_ddr_1_8v: mmc2_pins_ddr_1_8v {
		pinctrl-single,pins = <
			0x9c (PIN_INPUT_PULLUP | MODE_SELECT | MUX_MODE1) /* gpmc_a23.mmc2_clk */
			0xb0 (PIN_INPUT_PULLUP | MODE_SELECT | MUX_MODE1) /* gpmc_cs1.mmc2_cmd */
			0xa0 (PIN_INPUT_PULLUP | MODE_SELECT | MUX_MODE1) /* gpmc_a24.mmc2_dat0 */
			0xa4 (PIN_INPUT_PULLUP | MODE_SELECT | MUX_MODE1) /* gpmc_a25.mmc2_dat1 */
			0xa8 (PIN_INPUT_PULLUP | MODE_SELECT | MUX_MODE1) /* gpmc_a26.mmc2_dat2 */
			0xac (PIN_INPUT_PULLUP | MODE_SELECT | MUX_MODE1) /* gpmc_a27.mmc2_dat3 */
			0x8c (PIN_INPUT_PULLUP | MODE_SELECT | MUX_MODE1) /* gpmc_a19.mmc2_dat4 */
			0x90 (PIN_INPUT_PULLUP | MODE_SELECT | MUX_MODE1) /* gpmc_a20.mmc2_dat5 */
			0x94 (PIN_INPUT_PULLUP | MODE_SELECT | MUX_MODE1) /* gpmc_a21.mmc2_dat6 */
			0x98 (PIN_INPUT_PULLUP | MODE_SELECT | MUX_MODE1) /* gpmc_a22.mmc2_dat7 */
		>;
	};

	mmc3_pins_default: mmc3_pins_default {
		pinctrl-single,pins = <
			0x37c (PIN_INPUT_PULLUP | MUX_MODE0) /* mmc3_clk.clk */
			0x380 (PIN_INPUT_PULLUP | MUX_MODE0) /* mmc3_cmd.cmd */
			0x384 (PIN_INPUT_PULLUP | MUX_MODE0) /* mmc3_dat0.dat0 */
			0x388 (PIN_INPUT_PULLUP | MUX_MODE0) /* mmc3_dat1.dat1 */
			0x38c (PIN_INPUT_PULLUP | MUX_MODE0) /* mmc3_dat2.dat2 */
			0x390 (PIN_INPUT_PULLUP | MUX_MODE0) /* mmc3_dat3.dat3 */	
		>;
	};

	mmc3_pins_hs: mmc3_pins_hs {
		pinctrl-single,pins = <
			0x37c (PIN_INPUT_PULLUP | MUX_MODE0) /* mmc3_clk.clk */
			0x380 (PIN_INPUT_PULLUP | MUX_MODE0) /* mmc3_cmd.cmd */
			0x384 (PIN_INPUT_PULLUP | MUX_MODE0) /* mmc3_dat0.dat0 */
			0x388 (PIN_INPUT_PULLUP | MUX_MODE0) /* mmc3_dat1.dat1 */
			0x38c (PIN_INPUT_PULLUP | MUX_MODE0) /* mmc3_dat2.dat2 */
			0x390 (PIN_INPUT_PULLUP | MUX_MODE0) /* mmc3_dat3.dat3 */	
		>;
	};

	mmc3_pins_sdr12: pinmux_mmc3_sdr12_pins {
		pinctrl-single,pins = <
			0x37c (PIN_INPUT_PULLUP | MUX_MODE0)	/* mmc3_clk.clk */
			0x380 (PIN_INPUT_PULLUP | MUX_MODE0)	/* mmc3_cmd.cmd */
			0x384 (PIN_INPUT_PULLUP | MUX_MODE0)	/* mmc3_dat0.dat0 */
			0x388 (PIN_INPUT_PULLUP | MUX_MODE0)	/* mmc3_dat1.dat1 */
			0x38c (PIN_INPUT_PULLUP | MUX_MODE0)	/* mmc3_dat2.dat2 */
			0x390 (PIN_INPUT_PULLUP | MUX_MODE0)	/* mmc3_dat3.dat3 */
		>;
	};

	mmc3_pins_sdr25: pinmux_mmc3_sdr25_pins {
		pinctrl-single,pins = <
			0x37c (PIN_INPUT_PULLUP | MUX_MODE0)	/* mmc3_clk.clk */
			0x380 (PIN_INPUT_PULLUP | MUX_MODE0)	/* mmc3_cmd.cmd */
			0x384 (PIN_INPUT_PULLUP | MUX_MODE0)	/* mmc3_dat0.dat0 */
			0x388 (PIN_INPUT_PULLUP | MUX_MODE0)	/* mmc3_dat1.dat1 */
			0x38c (PIN_INPUT_PULLUP | MUX_MODE0)	/* mmc3_dat2.dat2 */
			0x390 (PIN_INPUT_PULLUP | MUX_MODE0)	/* mmc3_dat3.dat3 */
		>;
	};

	mmc3_pins_sdr50: pinmux_mmc3_sdr50_pins {
		pinctrl-single,pins = <
			0x37c (PIN_INPUT_PULLUP | MODE_SELECT | MUX_MODE0)	/* mmc3_clk.clk */
			0x380 (PIN_INPUT_PULLUP | MODE_SELECT | MUX_MODE0)	/* mmc3_cmd.cmd */
			0x384 (PIN_INPUT_PULLUP | MODE_SELECT | MUX_MODE0)	/* mmc3_dat0.dat0 */
			0x388 (PIN_INPUT_PULLUP | MODE_SELECT | MUX_MODE0)	/* mmc3_dat1.dat1 */
			0x38c (PIN_INPUT_PULLUP | MODE_SELECT | MUX_MODE0)	/* mmc3_dat2.dat2 */
			0x390 (PIN_INPUT_PULLUP | MODE_SELECT | MUX_MODE0)	/* mmc3_dat3.dat3 */
		>;
	};

	//brcm_wifi_reset: brcm_wifi_reset {
	//	pinctrl-single,pins = <
	//		DRA7XX_CORE_IOPAD(0x37c0, PIN_OUTPUT_PULLUP | MUX_MODE14) /*WL_REG_ON A26.spi2_sclk.gpio7_14  */
	//		DRA7XX_CORE_IOPAD(0x35d0, PIN_OUTPUT_PULLUP | MUX_MODE14) /*WL_HOST_WAKE AB8.mmc3_dat6.gpio1_24 */
	//	>;
	//};

        qspi1_pins_default: qspi1_pins_default {
                pinctrl-single,pins = <
                        DRA7XX_CORE_IOPAD(0x3488, (PIN_INPUT_PULLUP | MUX_MODE1)) /* gpmc_a18.qspi1_sclk */
                        DRA7XX_CORE_IOPAD(0x3474, (PIN_INPUT_PULLUP | MUX_MODE1)) /* gpmc_a13.qspi1_rtclk */
                        DRA7XX_CORE_IOPAD(0x3480, (PIN_INPUT_PULLUP | MUX_MODE1)) /* gpmc_a16.qspi1_d0 */
                        DRA7XX_CORE_IOPAD(0x3484, (PIN_INPUT_PULLUP | MUX_MODE1)) /* gpmc_a17.qspi1_d1 */
                        DRA7XX_CORE_IOPAD(0x347c, (PIN_INPUT_PULLUP | MUX_MODE1)) /* gpmc_a15.qspi1_d2 */
                        DRA7XX_CORE_IOPAD(0x3478, (PIN_INPUT_PULLUP | MUX_MODE1)) /* gpmc_a14.qspi1_d3 */
                        DRA7XX_CORE_IOPAD(0x34b8, (PIN_INPUT_PULLUP | MUX_MODE1)) /* gpmc_cs2.qspi1_cs0 */
                >;
        };

        spi3_pins: spi3_pins {
                pinctrl-single,pins = <
                        DRA7XX_CORE_IOPAD(0x36d4, (INPUT_EN | MUX_MODE3))          /* mcasp1_axr8.spi3_sclk (B12) */
                        DRA7XX_CORE_IOPAD(0x36d8, (INPUT_EN | MUX_MODE3))          /* mcasp1_axr9.spi3_d1 (A11) */
                        DRA7XX_CORE_IOPAD(0x36dc, (INPUT_EN | MUX_MODE3))          /* mcasp1_axr10.spi3_d0 (B13) */
                        DRA7XX_CORE_IOPAD(0x36e0, (PIN_OUTPUT_PULLUP | MUX_MODE3)) /* mcasp1_axr11.spi3_cs0 (A12) */
                >;
        };

       vin1a_pins: vin1a_pins {
               pinctrl-single,pins = <
                       DRA7XX_CORE_IOPAD(0x34DC, ((1 << 18))|PIN_OUTPUT_PULLUP | MUX_MODE0) /* vout1_clk */
                       DRA7XX_CORE_IOPAD(0x34E4, ((1 << 18))|PIN_OUTPUT_PULLUP | 0xE) /* de_clk */
                       DRA7XX_CORE_IOPAD(0x34E8, ((1 << 18))|PIN_OUTPUT_PULLUP | 0xE) /* fdl_clk */
                       DRA7XX_CORE_IOPAD(0x34EC, ((1 << 18))|PIN_OUTPUT_PULLUP | MUX_MODE0) /* vout1_hsync */
                       DRA7XX_CORE_IOPAD(0x34F0, (1 << 24)|((1 << 18))|PIN_OUTPUT_PULLUP | MUX_MODE0) /* vout1_vsync */
                       DRA7XX_CORE_IOPAD(0x34F4, ((1 << 18))|PIN_OUTPUT_PULLUP | MUX_MODE0) /* vout1_d0 */
                       DRA7XX_CORE_IOPAD(0x34F8, ((1 << 18))|PIN_OUTPUT_PULLUP | MUX_MODE0) /* vout1_d1 */
                       DRA7XX_CORE_IOPAD(0x34FC, ((1 << 18))|PIN_OUTPUT_PULLUP | MUX_MODE0) /* vout1_d2 */
                       DRA7XX_CORE_IOPAD(0x3500, ((1 << 18))|PIN_OUTPUT_PULLUP | MUX_MODE0) /* vout1_d3 */
                       DRA7XX_CORE_IOPAD(0x3504, ((1 << 18))|PIN_OUTPUT_PULLUP | MUX_MODE0) /* vout1_d4 */
                       DRA7XX_CORE_IOPAD(0x3508, ((1 << 18))|PIN_OUTPUT_PULLUP | MUX_MODE0) /* vout1_d5 */
                       DRA7XX_CORE_IOPAD(0x350C, ((1 << 18))|PIN_OUTPUT_PULLUP | MUX_MODE0) /* vout1_d6 */
                       DRA7XX_CORE_IOPAD(0x3510, ((1 << 18))|PIN_OUTPUT_PULLUP | MUX_MODE0) /* vout1_d7 */
		       
//                       DRA7XX_CORE_IOPAD(0x3514, ((1 << 18))|PIN_OUTPUT_PULLUP | MUX_MODE0) /* vout1_d8 */
//                       DRA7XX_CORE_IOPAD(0x3518, ((1 << 18))|PIN_OUTPUT_PULLUP | MUX_MODE0) /* vout1_d9 */
//                       DRA7XX_CORE_IOPAD(0x351C, ((1 << 18))|PIN_OUTPUT_PULLUP | MUX_MODE0) /* vout1_d10 */
//                       DRA7XX_CORE_IOPAD(0x3520, ((1 << 18))|PIN_OUTPUT_PULLUP | MUX_MODE0) /* vout1_d11 */
//                       DRA7XX_CORE_IOPAD(0x3524, ((1 << 18))|PIN_OUTPUT_PULLUP | MUX_MODE0) /* vout1_d12 */
//                       DRA7XX_CORE_IOPAD(0x3528, ((1 << 18))|PIN_OUTPUT_PULLUP | MUX_MODE0) /* vout1_d13 */
//                       DRA7XX_CORE_IOPAD(0x352c, ((1 << 18))|PIN_OUTPUT_PULLUP | MUX_MODE0) /* vout1_d14 */
//                       DRA7XX_CORE_IOPAD(0x3530, ((1 << 18))|PIN_OUTPUT_PULLUP | MUX_MODE0) /* vout1_d15 */
//                       DRA7XX_CORE_IOPAD(0x3534, ((1 << 18))|PIN_OUTPUT_PULLUP | MUX_MODE0) /* vout1_d16 */
//                       DRA7XX_CORE_IOPAD(0x3538, ((1 << 18))|PIN_OUTPUT_PULLUP | MUX_MODE0) /* vout1_d17 */
//                       DRA7XX_CORE_IOPAD(0x353C, ((1 << 18))|PIN_OUTPUT_PULLUP | MUX_MODE0) /* vout1_d18 */
//                       DRA7XX_CORE_IOPAD(0x3540, ((1 << 18))|PIN_OUTPUT_PULLUP | MUX_MODE0) /* vout1_d19 */
//                       DRA7XX_CORE_IOPAD(0x3544, ((1 << 18))|PIN_OUTPUT_PULLUP | MUX_MODE0) /* vout1_d20 */
//                       DRA7XX_CORE_IOPAD(0x3548, ((1 << 18))|PIN_OUTPUT_PULLUP | MUX_MODE0) /* vout1_d21 */
//                       DRA7XX_CORE_IOPAD(0x354c, ((1 << 18))|PIN_OUTPUT_PULLUP | MUX_MODE0) /* vout1_d22 */
//                       DRA7XX_CORE_IOPAD(0x3550, ((1 << 18))|PIN_OUTPUT_PULLUP | MUX_MODE0) /* vout1_d23 */
		       
          >;
	};
       vin2a_pins: vin2a_pins {
               pinctrl-single,pins = <
                       DRA7XX_CORE_IOPAD(0x3554, ((1 << 18))|PIN_OUTPUT_PULLUP | MUX_MODE0) /* vout1_clk */
                       DRA7XX_CORE_IOPAD(0x3560, ((1 << 18))|PIN_OUTPUT_PULLUP | MUX_MODE0) /* vout1_hsync */
                       DRA7XX_CORE_IOPAD(0x3564, (1 << 24)|((1 << 18))|PIN_OUTPUT_PULLUP | MUX_MODE0) /* vout1_vsync */
                       DRA7XX_CORE_IOPAD(0x3568, ((1 << 18))|PIN_OUTPUT_PULLUP | MUX_MODE0) /* vout1_d0 */
                       DRA7XX_CORE_IOPAD(0x356c, ((1 << 18))|PIN_OUTPUT_PULLUP | MUX_MODE0) /* vout1_d1 */
                       DRA7XX_CORE_IOPAD(0x3570, ((1 << 18))|PIN_OUTPUT_PULLUP | MUX_MODE0) /* vout1_d2 */
                       DRA7XX_CORE_IOPAD(0x3574, ((1 << 18))|PIN_OUTPUT_PULLUP | MUX_MODE0) /* vout1_d3 */
                       DRA7XX_CORE_IOPAD(0x3578, ((1 << 18))|PIN_OUTPUT_PULLUP | MUX_MODE0) /* vout1_d4 */
                       DRA7XX_CORE_IOPAD(0x357c, ((1 << 18))|PIN_OUTPUT_PULLUP | MUX_MODE0) /* vout1_d5 */
                       DRA7XX_CORE_IOPAD(0x3580, ((1 << 18))|PIN_OUTPUT_PULLUP | MUX_MODE0) /* vout1_d6 */
                       DRA7XX_CORE_IOPAD(0x3584, ((1 << 18))|PIN_OUTPUT_PULLUP | MUX_MODE0) /* vout1_d7 */
		>;
	};
};

&dra7_iodelay_core {
	mmc1_iodelay_ddr50_conf: mmc1_iodelay_ddr50_conf {
		pinctrl-pin-array = <
			0x618 A_DELAY_PS(0) G_DELAY_PS(0)		/* CFG_MMC1_CLK_IN */
			0x624 A_DELAY_PS(0) G_DELAY_PS(0)		/* CFG_MMC1_CMD_IN */
			0x630 A_DELAY_PS(495) G_DELAY_PS(0)	/* CFG_MMC1_DAT0_IN */
			0x63C A_DELAY_PS(116) G_DELAY_PS(0)	/* CFG_MMC1_DAT1_IN */
			0x648 A_DELAY_PS(117) G_DELAY_PS(0)	/* CFG_MMC1_DAT2_IN */
			0x654 A_DELAY_PS(32) G_DELAY_PS(0)	/* CFG_MMC1_DAT3_IN */
			0x620 A_DELAY_PS(1224) G_DELAY_PS(0)	/* CFG_MMC1_CLK_OUT */
			0x62C A_DELAY_PS(0) G_DELAY_PS(0)		/* CFG_MMC1_CMD_OUT */
			0x638 A_DELAY_PS(44) G_DELAY_PS(0)	/* CFG_MMC1_DAT0_OUT */
			0x644 A_DELAY_PS(64) G_DELAY_PS(0)	/* CFG_MMC1_DAT1_OUT */
			0x650 A_DELAY_PS(79) G_DELAY_PS(0)	/* CFG_MMC1_DAT2_OUT */
			0x65C A_DELAY_PS(87) G_DELAY_PS(0)	/* CFG_MMC1_DAT3_OUT */
			0x628 A_DELAY_PS(0) G_DELAY_PS(0)		/* CFG_MMC1_CMD_OEN */
			0x634 A_DELAY_PS(0) G_DELAY_PS(0)		/* CFG_MMC1_DAT0_OEN */
			0x640 A_DELAY_PS(0) G_DELAY_PS(0)		/* CFG_MMC1_DAT1_OEN */
			0x64C A_DELAY_PS(0) G_DELAY_PS(0)		/* CFG_MMC1_DAT2_OEN */
			0x658 A_DELAY_PS(0) G_DELAY_PS(0)		/* CFG_MMC1_DAT3_OEN */
		>;
	};

	mmc1_iodelay_sdr104_conf: mmc1_iodelay_sdr104_conf {
		pinctrl-pin-array = <
			0x620 A_DELAY_PS(520) G_DELAY_PS(320)	/* CFG_MMC1_CLK_OUT */
			0x62c A_DELAY_PS(0) G_DELAY_PS(0)		/* CFG_MMC1_CMD_OUT */
			0x638 A_DELAY_PS(40) G_DELAY_PS(0)	/* CFG_MMC1_DAT0_OUT */
			0x644 A_DELAY_PS(83) G_DELAY_PS(0)	/* CFG_MMC1_DAT1_OUT */
			0x650 A_DELAY_PS(98) G_DELAY_PS(0)	/* CFG_MMC1_DAT2_OUT */
			0x65c A_DELAY_PS(106) G_DELAY_PS(0)	/* CFG_MMC1_DAT3_OUT */
			0x628 A_DELAY_PS(51) G_DELAY_PS(0)	/* CFG_MMC1_CMD_OEN */
			0x634 A_DELAY_PS(0) G_DELAY_PS(0)		/* CFG_MMC1_DAT0_OEN */
			0x640 A_DELAY_PS(363) G_DELAY_PS(0)	/* CFG_MMC1_DAT1_OEN */
			0x64c A_DELAY_PS(199) G_DELAY_PS(0)	/* CFG_MMC1_DAT2_OEN */
			0x658 A_DELAY_PS(273) G_DELAY_PS(0)	/* CFG_MMC1_DAT3_OEN */
		>;
	};

	mmc2_iodelay_ddr_1_8v_conf: mmc2_iodelay_ddr_1_8v_conf {
		pinctrl-pin-array = <
			0x18c A_DELAY_PS(0) G_DELAY_PS(0)		/* CFG_GPMC_A19_IN */
			0x1a4 A_DELAY_PS(121) G_DELAY_PS(0)	/* CFG_GPMC_A20_IN */
			0x1b0 A_DELAY_PS(0) G_DELAY_PS(0)		/* CFG_GPMC_A21_IN */
			0x1bc A_DELAY_PS(20) G_DELAY_PS(0)	/* CFG_GPMC_A22_IN */
			0x1c8 A_DELAY_PS(108) G_DELAY_PS(0)	/* CFG_GPMC_A23_IN */
			0x1d4 A_DELAY_PS(31) G_DELAY_PS(0)	/* CFG_GPMC_A24_IN */
			0x1e0 A_DELAY_PS(0) G_DELAY_PS(0)		/* CFG_GPMC_A25_IN */
			0x1ec A_DELAY_PS(24) G_DELAY_PS(0)	/* CFG_GPMC_A26_IN */
			0x1f8 A_DELAY_PS(0) G_DELAY_PS(0)		/* CFG_GPMC_A27_IN */
			0x360 A_DELAY_PS(0) G_DELAY_PS(0)		/* CFG_GPMC_CS1_IN */
			0x194 A_DELAY_PS(152) G_DELAY_PS(0)	/* CFG_GPMC_A19_OUT */
			0x1ac A_DELAY_PS(206) G_DELAY_PS(0)	/* CFG_GPMC_A20_OUT */
			0x1b8 A_DELAY_PS(78) G_DELAY_PS(0)	/* CFG_GPMC_A21_OUT */
			0x1c4 A_DELAY_PS(2) G_DELAY_PS(0)		/* CFG_GPMC_A22_OUT */
			0x1d0 A_DELAY_PS(266) G_DELAY_PS(0)	/* CFG_GPMC_A23_OUT */
			0x1dc A_DELAY_PS(0) G_DELAY_PS(0)		/* CFG_GPMC_A24_OUT */
			0x1e8 A_DELAY_PS(0) G_DELAY_PS(0)		/* CFG_GPMC_A25_OUT */
			0x1f4 A_DELAY_PS(43) G_DELAY_PS(0)	/* CFG_GPMC_A26_OUT */
			0x200 A_DELAY_PS(0) G_DELAY_PS(0)		/* CFG_GPMC_A27_OUT */
			0x368 A_DELAY_PS(0) G_DELAY_PS(0)		/* CFG_GPMC_CS1_OUT */
			0x190 A_DELAY_PS(0) G_DELAY_PS(0)		/* CFG_GPMC_A19_OEN */
			0x1a8 A_DELAY_PS(0) G_DELAY_PS(0)		/* CFG_GPMC_A20_OEN */
			0x1b4 A_DELAY_PS(0) G_DELAY_PS(0)		/* CFG_GPMC_A21_OEN */
			0x1c0 A_DELAY_PS(0) G_DELAY_PS(0)		/* CFG_GPMC_A22_OEN */
			0x1d8 A_DELAY_PS(0) G_DELAY_PS(0)		/* CFG_GPMC_A24_OEN */
			0x1e4 A_DELAY_PS(0) G_DELAY_PS(0)		/* CFG_GPMC_A25_OEN */
			0x1f0 A_DELAY_PS(0) G_DELAY_PS(0)		/* CFG_GPMC_A26_OEN */
			0x1fc A_DELAY_PS(0) G_DELAY_PS(0)		/* CFG_GPMC_A27_OEN */
			0x364 A_DELAY_PS(0) G_DELAY_PS(0)		/* CFG_GPMC_CS1_OEN */
		>;
	};
};

#include "am57xx-evm-cmem.dtsi"
